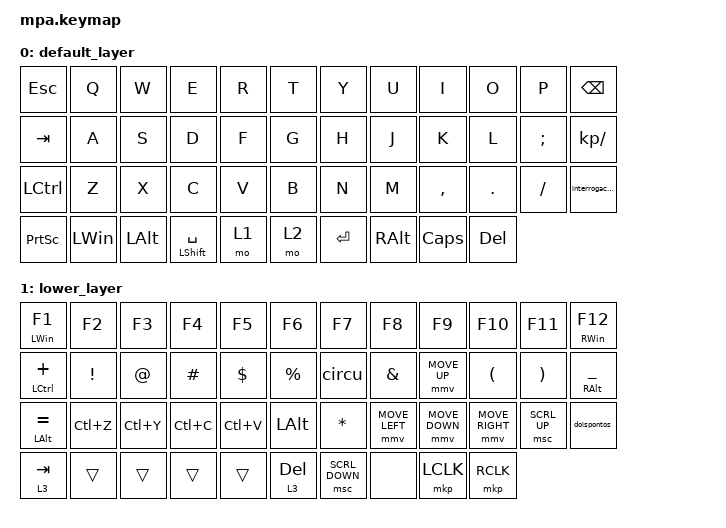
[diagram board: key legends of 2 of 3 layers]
/*
 * Copyright (c) 2020 The ZMK Contributors
 *
 * SPDX-License-Identifier: MIT
 */

#include <behaviors.dtsi>
#include <dt-bindings/zmk/keys.h>
#include <dt-bindings/zmk/pointing.h>
#include "zmk-helpers/helper.h"
#include "zmk-helpers/unicode-chars/portuguese.dtsi"

#define DEF 0
#define LWR 1
#define RSE 2
#define ADJ 3

&lt { quick_tap_ms = <220>; };

&mt { quick_tap_ms = <220>; };

/ {
    macros {
        numdot: numdot {
            label = "ZM_numdot";
            compatible = "zmk,behavior-macro";
            #binding-cells = <0>;
            wait-ms = <40>;
            tap-ms = <40>;
            bindings =
                <&macro_press>,
                <&kp LALT>,
                <&macro_tap>,
                <&kp KP_N4 &kp KP_N6>,
                <&macro_release>,
                <&kp LALT>;
        };

        grtsgn: grtsgn {
            label = "ZM_grtsgn";
            compatible = "zmk,behavior-macro";
            #binding-cells = <0>;
            wait-ms = <40>;
            tap-ms = <40>;
            bindings =
                <&macro_press>,
                <&kp LALT>,
                <&macro_tap>,
                <&kp KP_N6 &kp KP_N2>,
                <&macro_release>,
                <&kp LALT>;
        };

        doispontos: doispontos {
        compatible = "zmk,behavior-macro";
        #binding-cells = <0>;
         bindings =
           <&macro_press>,
           <&kp LEFT_ALT>,
           <&macro_tap>,
           <&kp KP_NUMBER_5 &kp KP_NUMBER_8>,
           <&macro_release>,
           <&kp LEFT_ALT>;

            label = "DOIS_PONTOS";
         };

       interrogacao: new_macro_assc {
            compatible = "zmk,behavior-macro";
            #binding-cells = <0>;
            bindings =
                <&macro_press>,
                <&kp LEFT_ALT>,
                <&macro_tap>,
                <&kp KP_NUMBER_6 &kp KP_NUMBER_3>,
                <&macro_release>,
                <&kp LEFT_ALT>;

            label = "NEW_MACRO_ASSC";
        };

        aspas: apostofro {
            compatible = "zmk,behavior-macro";
            #binding-cells = <0>;
            bindings =
                <&macro_press>,
                <&kp LEFT_ALT>,
                <&macro_tap>,
                <&kp KP_NUMBER_3 &kp KP_NUMBER_9>,
                <&macro_release>,
                <&kp LEFT_ALT>;

            label = "APOSTOFRO";
        };

        aspas_dupla: aspas_dupla {
            compatible = "zmk,behavior-macro";
            #binding-cells = <0>;
            bindings =
                <&macro_press>,
                <&kp LEFT_ALT>,
                <&macro_tap>,
                <&kp KP_NUMBER_3 &kp KP_NUMBER_4>,
                <&macro_release>,
                <&kp LEFT_ALT>;

            label = "ASPAS_DUPLA";
        };

        layer1: layer1 {
            compatible = "zmk,behavior-macro";
            #binding-cells = <0>;
            bindings =
                <&macro_press>,
                <&mo 1 &kp F14>,
                <&macro_pause_for_release>,
                <&macro_release>,
                <&mo 1 &kp F14>;

            label = "LAYER1";
        };

        layer2: layer2 {
            compatible = "zmk,behavior-macro";
            #binding-cells = <0>;
            bindings =
                <&macro_press>,
                <&mo 2 &kp F15>,
                <&macro_pause_for_release>,
                <&macro_release>,
                <&mo 2 &kp F15>;

            label = "LAYER2";
        };

        circu: circu {
            compatible = "zmk,behavior-macro";
            #binding-cells = <0>;
            bindings =
                <&macro_press>,
                <&kp LEFT_ALT>,
                <&macro_tap>,
                <&kp KP_NUMBER_9 &kp KP_NUMBER_4>,
                <&macro_release>,
                <&kp LEFT_ALT>;

            label = "CIRCU";
        };
    };
};

/ {
    keymap {
        compatible = "zmk,keymap";

        default_layer {
            bindings = <
&kp ESCAPE        &kp Q         &kp W         &kp E                 &kp R  &kp T  &kp Y      &kp U          &kp I         &kp O       &kp P          &kp BACKSPACE
&kp TAB           &kp A         &kp S         &kp D                 &kp F  &kp G  &kp H      &kp J          &kp K         &kp L       &kp SEMICOLON  &kp KP_SLASH
&kp LEFT_CONTROL  &kp Z         &kp X         &kp C                 &kp V  &kp B  &kp N      &kp M          &kp COMMA     &kp DOT     &kp SLASH      &interrogacao
&kp PRINTSCREEN   &kp LEFT_WIN  &kp LEFT_ALT  &mt LEFT_SHIFT SPACE  &mo 1  &mo 2  &kp ENTER  &kp RIGHT_ALT  &kp CAPSLOCK  &kp DELETE
            >;
        };

        lower_layer {
            bindings = <
&mt LWIN F1     &kp F2     &kp F3     &kp F4     &kp F5      &kp F6        &kp F7          &kp F8          &kp F9          &kp F10          &kp F11       &mt RWIN F12
&mt LCTRL PLUS  &kp EXCL   &kp AT     &kp HASH   &kp DOLLAR  &kp PERCENT   &circu          &kp AMPS        &mmv MOVE_UP    &kp LPAR         &kp RPAR      &mt RALT UNDER
&mt LALT EQUAL  &kp LC(Z)  &kp LC(Y)  &kp LC(C)  &kp LC(V)   &kp LEFT_ALT  &kp ASTERISK    &mmv MOVE_LEFT  &mmv MOVE_DOWN  &mmv MOVE_RIGHT  &msc SCRL_UP  &doispontos
&lt 3 TAB       &trans     &trans     &trans     &trans      &lt 3 DEL     &msc SCRL_DOWN  &none           &mkp LCLK       &mkp RCLK
            >;
        };

        raise_layer {
            bindings = <
&mt LEFT_GUI KP_NUMLOCK  &kp KP_SLASH  &none           &kp UP          &kp HOME   &kp PAGE_UP    &kp LEFT_BRACKET      &kp KP_NUMBER_7  &kp KP_NUMBER_8  &kp KP_NUMBER_9  &kp RIGHT_BRACKET  &kp BACKSLASH
&mt LCTRL KP_PLUS        &none         &kp LEFT        &kp DOWN        &kp RIGHT  &kp PAGE_DOWN  &kp SQT               &kp KP_NUMBER_4  &kp KP_NUMBER_5  &kp KP_NUMBER_6  &kp MINUS          &kp LS(MINUS)
&mt LALT EQUAL           &kp LC(Z)     &kp LC(Y)       &kp LC(C)       &kp LC(V)  &kp END        &kp LS(APOSTROPHE)    &kp KP_NUMBER_1  &kp KP_NUMBER_2  &kp KP_NUMBER_3  &aspas             &aspas_dupla
&trans                   &trans        &kp KP_NUMLOCK  &kp LEFT_SHIFT  &trans     &trans         &kp LS(LEFT_BRACKET)  &kp PERIOD       &kp KP_NUMBER_0  &kp LS(APOS)     &bootloader        &kt PLUS
            >;
        };
    };
};
